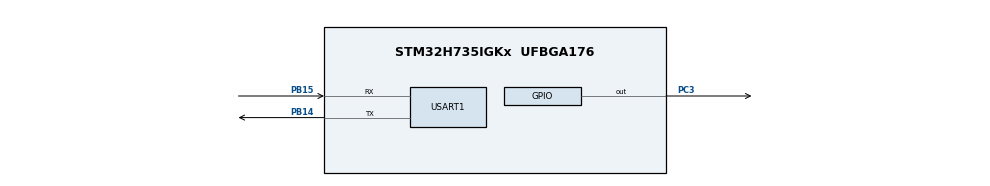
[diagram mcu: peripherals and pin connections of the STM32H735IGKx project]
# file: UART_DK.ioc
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Mcu.Family=STM32H7
Mcu.Name=STM32H735IGKx
Mcu.Package=UFBGA176
NVIC.PriorityGroup=NVIC_PRIORITYGROUP_4
NVIC.USART1_IRQn=true\:0\:0\:false\:false\:true\:true\:true\:true
PB14.Mode=Asynchronous
PB14.Signal=USART1_TX
PB15.Mode=Asynchronous
PB15.Signal=USART1_RX
PC3.Signal=GPIO_Output
PH0-OSC_IN.Mode=HSE-External-Oscillator
PH0-OSC_IN.Signal=RCC_OSC_IN
PH1-OSC_OUT.Mode=HSE-External-Oscillator
PH1-OSC_OUT.Signal=RCC_OSC_OUT
ProjectManager.HeapSize=0x200
ProjectManager.StackSize=0x400
ProjectManager.TargetToolchain=STM32CubeIDE
RCC.ADCFreq_Value=80000000
RCC.APB1Freq_Value=48750000
RCC.APB2Freq_Value=48750000
RCC.APB3Freq_Value=48750000
RCC.APB4Freq_Value=48750000
RCC.CortexFreq_Value=195000000
RCC.D1PPRE=RCC_APB3_DIV2
RCC.D2PPRE1=RCC_APB1_DIV2
RCC.D2PPRE2=RCC_APB2_DIV2
RCC.D3PPRE=RCC_APB4_DIV2
RCC.DIVM1=5
RCC.DIVM2=5
RCC.DIVN1=39
RCC.DIVN2=80
RCC.DIVP1=1
RCC.DIVP2=5
RCC.DIVQ1=4
RCC.HCLKFreq_Value=97500000
RCC.HPRE=RCC_HCLK_DIV2
RCC.PLL2FRACN=0
RCC.PLL3FRACN=0
RCC.PLLFRACN=0
RCC.PLLSourceVirtual=RCC_PLLSOURCE_HSE
RCC.SYSCLKFreq_VALUE=195000000
RCC.SYSCLKSource=RCC_SYSCLKSOURCE_PLLCLK
RCC.USBCLockSelection=RCC_USBCLKSOURCE_HSI48
RCC.USBFreq_Value=48000000
USART1.VirtualMode-Asynchronous=VM_ASYNC
VP_MEMORYMAP_VS_MEMORYMAP.Mode=CurAppReg
board=STM32H735G-DK

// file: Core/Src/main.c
/* USER CODE BEGIN Header */
/**
  ******************************************************************************
  * @file           : main.c
  * @brief          : Main program body
  ******************************************************************************
  * @attention
  *
  * Copyright (c) 2025 STMicroelectronics.
  * All rights reserved.
  *
  * This software is licensed under terms that can be found in the LICENSE file
  * in the root directory of this software component.
  * If no LICENSE file comes with this software, it is provided AS-IS.
  *
  ******************************************************************************
  */
/* USER CODE END Header */
#include "main.h"

/* USER CODE BEGIN Includes */
#include<string.h>

/* USER CODE END Includes */

UART_HandleTypeDef huart1;

void SystemClock_Config(void);
static void MX_GPIO_Init(void);
static void MX_USART1_UART_Init(void);

int main(void)
{

  /* MCU Configuration--------------------------------------------------------*/

  /* Reset of all peripherals, Initializes the Flash interface and the Systick. */
  HAL_Init();

  /* Configure the system clock */
  SystemClock_Config();

  /* Initialize all configured peripherals */
  MX_GPIO_Init();
  MX_USART1_UART_Init();

  /* Infinite loop */
  while (1)
  {

    /* USER CODE BEGIN 3 */
	  char msg[50]="HELLO";
	  //sprintf(msg, "Echoed back ID: 0x%lX Data: 0x%02X\r\n", (unsigned long)RxHeader.StdId, RxData[0]);
	  HAL_UART_Transmit(&huart1, (uint8_t*)msg, strlen(msg), HAL_MAX_DELAY);
	  HAL_GPIO_TogglePin(GPIOC, GPIO_PIN_3);
	  HAL_Delay(1000);
  }
  /* USER CODE END 3 */
}

void SystemClock_Config(void)
{
  RCC_OscInitTypeDef RCC_OscInitStruct = {0};
  RCC_ClkInitTypeDef RCC_ClkInitStruct = {0};

  /** Supply configuration update enable
  */
  HAL_PWREx_ConfigSupply(PWR_DIRECT_SMPS_SUPPLY);

  /** Configure the main internal regulator output voltage
  */
  __HAL_PWR_VOLTAGESCALING_CONFIG(PWR_REGULATOR_VOLTAGE_SCALE2);

  while(!__HAL_PWR_GET_FLAG(PWR_FLAG_VOSRDY)) {}

  /** Initializes the RCC Oscillators according to the specified parameters
  * in the RCC_OscInitTypeDef structure.
  */
  RCC_OscInitStruct.OscillatorType = RCC_OSCILLATORTYPE_HSE;
  RCC_OscInitStruct.HSEState = RCC_HSE_ON;
  RCC_OscInitStruct.PLL.PLLState = RCC_PLL_ON;
  RCC_OscInitStruct.PLL.PLLSource = RCC_PLLSOURCE_HSE;
  RCC_OscInitStruct.PLL.PLLM = 5;
  RCC_OscInitStruct.PLL.PLLN = 39;
  RCC_OscInitStruct.PLL.PLLP = 1;
  RCC_OscInitStruct.PLL.PLLQ = 4;
  RCC_OscInitStruct.PLL.PLLR = 2;
  RCC_OscInitStruct.PLL.PLLRGE = RCC_PLL1VCIRANGE_2;
  RCC_OscInitStruct.PLL.PLLVCOSEL = RCC_PLL1VCOWIDE;
  RCC_OscInitStruct.PLL.PLLFRACN = 0;
  if (HAL_RCC_OscConfig(&RCC_OscInitStruct) != HAL_OK)
  {
    Error_Handler();
  }

  /** Initializes the CPU, AHB and APB buses clocks
  */
  RCC_ClkInitStruct.ClockType = RCC_CLOCKTYPE_HCLK|RCC_CLOCKTYPE_SYSCLK
                              |RCC_CLOCKTYPE_PCLK1|RCC_CLOCKTYPE_PCLK2
                              |RCC_CLOCKTYPE_D3PCLK1|RCC_CLOCKTYPE_D1PCLK1;
  RCC_ClkInitStruct.SYSCLKSource = RCC_SYSCLKSOURCE_PLLCLK;
  RCC_ClkInitStruct.SYSCLKDivider = RCC_SYSCLK_DIV1;
  RCC_ClkInitStruct.AHBCLKDivider = RCC_HCLK_DIV2;
  RCC_ClkInitStruct.APB3CLKDivider = RCC_APB3_DIV2;
  RCC_ClkInitStruct.APB1CLKDivider = RCC_APB1_DIV2;
  RCC_ClkInitStruct.APB2CLKDivider = RCC_APB2_DIV2;
  RCC_ClkInitStruct.APB4CLKDivider = RCC_APB4_DIV2;

  if (HAL_RCC_ClockConfig(&RCC_ClkInitStruct, FLASH_LATENCY_1) != HAL_OK)
  {
    Error_Handler();
  }
}

static void MX_USART1_UART_Init(void)
{

  huart1.Instance = USART1;
  huart1.Init.BaudRate = 115200;
  huart1.Init.WordLength = UART_WORDLENGTH_8B;
  huart1.Init.StopBits = UART_STOPBITS_1;
  huart1.Init.Parity = UART_PARITY_NONE;
  huart1.Init.Mode = UART_MODE_TX_RX;
  huart1.Init.HwFlowCtl = UART_HWCONTROL_NONE;
  huart1.Init.OverSampling = UART_OVERSAMPLING_16;
  huart1.Init.OneBitSampling = UART_ONE_BIT_SAMPLE_DISABLE;
  huart1.Init.ClockPrescaler = UART_PRESCALER_DIV1;
  huart1.AdvancedInit.AdvFeatureInit = UART_ADVFEATURE_NO_INIT;
  if (HAL_UART_Init(&huart1) != HAL_OK)
  {
    Error_Handler();
  }
  if (HAL_UARTEx_SetTxFifoThreshold(&huart1, UART_TXFIFO_THRESHOLD_1_8) != HAL_OK)
  {
    Error_Handler();
  }
  if (HAL_UARTEx_SetRxFifoThreshold(&huart1, UART_RXFIFO_THRESHOLD_1_8) != HAL_OK)
  {
    Error_Handler();
  }
  if (HAL_UARTEx_DisableFifoMode(&huart1) != HAL_OK)
  {
    Error_Handler();
  }

}

static void MX_GPIO_Init(void)
{
  GPIO_InitTypeDef GPIO_InitStruct = {0};

  /* GPIO Ports Clock Enable */
  __HAL_RCC_GPIOH_CLK_ENABLE();
  __HAL_RCC_GPIOB_CLK_ENABLE();
  __HAL_RCC_GPIOC_CLK_ENABLE();

  /*Configure GPIO pin Output Level */
  HAL_GPIO_WritePin(GPIOC, GPIO_PIN_3, GPIO_PIN_RESET);

  /*Configure GPIO pin : PC3 */
  GPIO_InitStruct.Pin = GPIO_PIN_3;
  GPIO_InitStruct.Mode = GPIO_MODE_OUTPUT_PP;
  GPIO_InitStruct.Pull = GPIO_NOPULL;
  GPIO_InitStruct.Speed = GPIO_SPEED_FREQ_LOW;
  HAL_GPIO_Init(GPIOC, &GPIO_InitStruct);

  /*AnalogSwitch Config */
  HAL_SYSCFG_AnalogSwitchConfig(SYSCFG_SWITCH_PC3, SYSCFG_SWITCH_PC3_CLOSE);

}

void Error_Handler(void)
{
  __disable_irq();
  while (1)
  {
  }
}
